VERSION ""

NS_ :

BS_:

BU_:

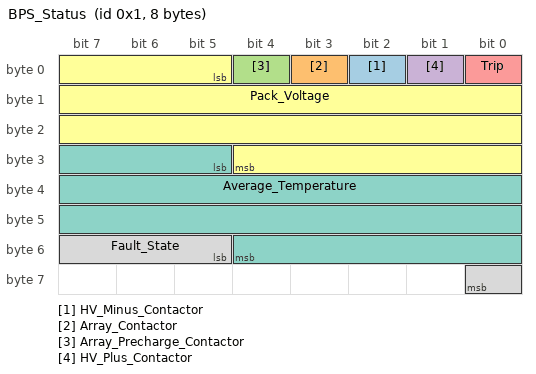
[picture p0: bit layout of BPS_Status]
BO_ 1 BPS_Status: 8 Vector__XXX
	SG_ HV_Minus_Contactor : 2|1@1+ (1,0) [0|1] "bool" Vector__XXX
	SG_ Array_Contactor : 3|1@1+ (1,0) [0|1] "bool" Vector__XXX
	SG_ Array_Precharge_Contactor : 4|1@1+ (1,0) [0|1] "bool" Vector__XXX
	SG_ HV_Plus_Contactor : 1|1@1+ (1,0) [0|1] "bool" Vector__XXX
	SG_ Trip : 0|1@1+ (1,0) [0|1] "bool" Vector__XXX
	SG_ Pack_Voltage : 5|24@1+ (1,0) [0|16777215] "mV" Vector__XXX
	SG_ Average_Temperature : 29|24@1+ (1,0) [0|16777215] "mC" Vector__XXX
	SG_ Fault_State : 53|4@1+ (1,0) [0|12] "bitfield" Vector__XXX

BO_ 81 BPS_Pack_Current: 4 Vector__XXX
	SG_ Current : 0|32@1- (1,0) [-40000|100000] "mA" Vector__XXX

BO_ 97 BPS_Module_Voltage: 5 Vector__XXX
	SG_ Module : 0|8@1+ (1,0) [0|31] "" Vector__XXX
	SG_ Voltage : 8|32@1+ (1,0) [0|1000000] "mV" Vector__XXX

BO_ 98 BPS_Module_Temperature: 5 Vector__XXX
	SG_ Module : 0|8@1+ (1,0) [0|31] "" Vector__XXX
	SG_ Temperature : 8|32@1+ (1,0) [0|1000000] "mC" Vector__XXX

BO_ 257 BPS_State_of_Charge: 4 Vector__XXX
	SG_ SoC : 0|32@1+ (1,0) [0|100] "%" Vector__XXX

CM_ BO_ 1 "BPS system status (10 Hz)";
CM_ SG_ 1 HV_Minus_Contactor "True when HV- contactor is closed. False when HV- contactor is open";
CM_ SG_ 1 Array_Contactor "True when array contactor is closed. False when array contactor is open";
CM_ SG_ 1 Array_Precharge_Contactor "True when array precharge contactor is closed. False when array precharge contactor is open";
CM_ SG_ 1 HV_Plus_Contactor "True when HV+ contactor is closed. False when HV+ contactor is open";
CM_ SG_ 1 Trip "True when BPS has opened HV+/- contactors due to a fault. False otherwise";
CM_ BO_ 81 "Instantaneous battery pack current (4 Hz)";
CM_ SG_ 81 Current "Instantaneous battery pack current";
CM_ BO_ 97 "Voltage of specified module (32 Hz)";
CM_ SG_ 97 Module "Module number for measurement";
CM_ SG_ 97 Voltage "Measured module voltage";
CM_ BO_ 98 "Temperature of specified module (32 Hz)";
CM_ SG_ 98 Module "Module number for measurement";
CM_ SG_ 98 Temperature "Measured module temperature";
CM_ BO_ 257 "Battery pack state of charge (1 Hz)";
CM_ SG_ 257 SoC "Battery pack state of charge";
BA_DEF_ BO_  "VFrameFormat" ENUM  "StandardCAN","ExtendedCAN","reserved","J1939PG";
BA_DEF_  "DatabaseVersion" STRING ;
BA_DEF_  "BusType" STRING ;
BA_DEF_  "ProtocolType" STRING ;
BA_DEF_  "DatabaseCompiler" STRING ;
BA_DEF_DEF_  "VFrameFormat" "J1939PG";
BA_DEF_DEF_  "DatabaseVersion" "DEMO PLUS";
BA_DEF_DEF_  "BusType" "";
BA_DEF_DEF_  "ProtocolType" "";
BA_DEF_DEF_  "DatabaseCompiler" "";
BA_ "ProtocolType" "J1939";
BA_ "BusType" "CAN";
BA_ "DatabaseCompiler" "CSS ELECTRONICS (WWW.CSSELECTRONICS.COM)";
BA_ "DatabaseVersion" "1.0.0";
